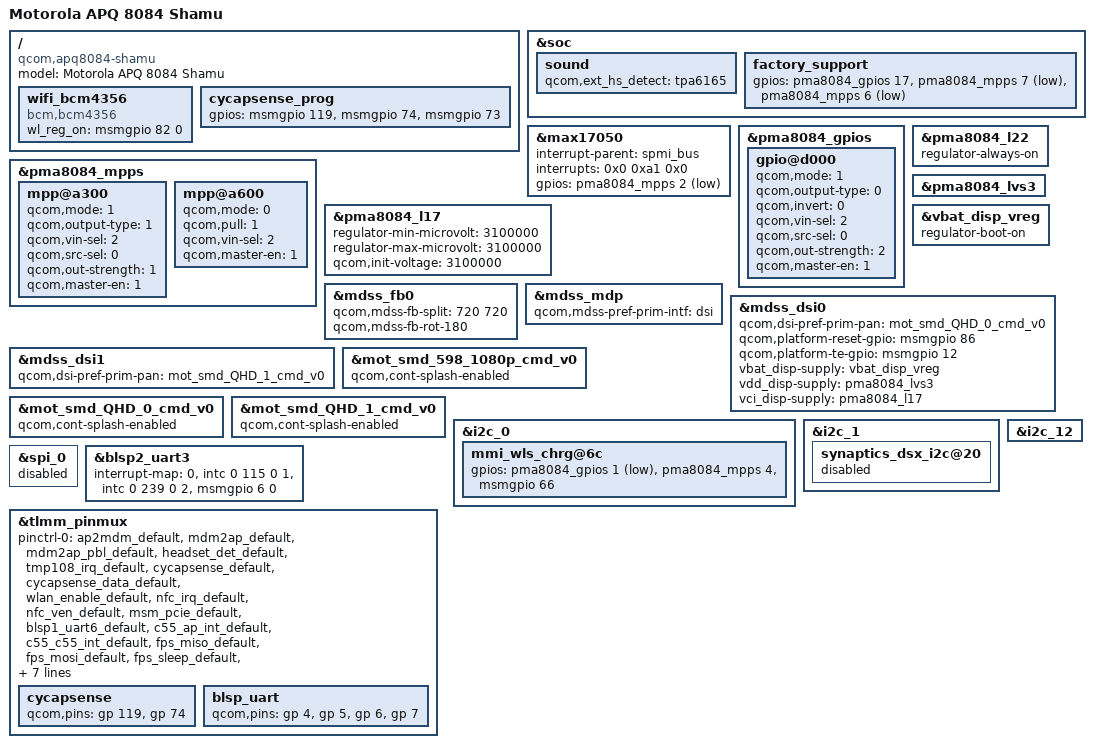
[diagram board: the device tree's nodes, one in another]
/* Copyright (c) 2013, The Linux Foundation. All rights reserved.
 * Copyright (c) 2014 Motorola Mobility LLC
 *
 * This program is free software; you can redistribute it and/or modify
 * it under the terms of the GNU General Public License version 2 and
 * only version 2 as published by the Free Software Foundation.
 *
 * This program is distributed in the hope that it will be useful,
 * but WITHOUT ANY WARRANTY; without even the implied warranty of
 * MERCHANTABILITY or FITNESS FOR A PARTICULAR PURPOSE.  See the
 * GNU General Public License for more details.
 */

#include "apq8084-moto-common.dtsi"
#include "dsi-panel-mot-dummy-qhd-video.dtsi"
#include "dsi-panel-mot-smd-QHD-cmd.dtsi"
#include "dsi-panel-mot-smd-598-1080p-cmd.dtsi"

/ {
	model = "Motorola APQ 8084 Shamu";
	compatible = "qcom,apq8084-shamu",
		   "qcom,apq8084-moto",
		   "qcom,apq8084";

	wifi_bcm4356 {
		compatible = "bcm,bcm4356";
		wl_reg_on = <&msmgpio 82 0>;
	};

	cycapsense_prog {
			gpios = <&msmgpio 119 0>, /* RESET */
				<&msmgpio 74 0>, /* programming SCLK */
				<&msmgpio 73 0>; /* programming SDAT */
	};

	/delete-node/ bt_qca6174;
};

&soc {
	sound {
		qcom,ext_hs_detect = "tpa6165";
	};

	factory_support {
		gpios = <&pma8084_gpios 17 0x0>, /* GPIOF_OUT_INIT_LOW */
			<&pma8084_mpps 7 0x1>, /* GPIOF_IN */
			<&pma8084_mpps 6 0x1>; /* GPIOF_IN */
	};

	/delete-node/ qcom,cnss@0d400000;
	/delete-node/ qca,qca1530;
};

&max17050 {
	interrupt-parent = <&spmi_bus>;
	interrupts = <0x0 0xa1 0x0>;    /* PMA8084 MPP 2 */
	gpios = <&pma8084_mpps 2 0x11>;  /* GPIOF_DIR_IN|GPIOF_EXPORT */
};

&pma8084_gpios {
	gpio@d000 { /* GPIO 17 */
		qcom,mode = <1>;		/* Digital output */
		qcom,output-type = <0>;		/* CMOS logic */
		qcom,invert = <0>;		/* Output low initially */
		qcom,vin-sel = <2>;		/* VIN 2 */
		qcom,src-sel = <0>;		/* GPIO */
		qcom,out-strength = <2>;	/* Medium */
		qcom,master-en = <1>;		/* Enable GPIO */
	};
};

&pma8084_mpps {
	mpp@a300 { /* MPP 4 */
		/* Wireless Charge Complete N */
		qcom,mode = <1>;		/* Digital output */
		qcom,output-type = <1>;		/* Open Drain NMOS logic */
		qcom,vin-sel = <2>;		/* VIN 2 */
		qcom,src-sel = <0>;		/* Constant */
		qcom,out-strength = <1>;	/* Low */
		qcom,master-en = <1>;		/* Enable GPIO */
	};
	mpp@a600 { /* MPP 7 */
		qcom,mode = <0>;          /* QPNP_PIN_MODE_DIG_IN */
		qcom,pull = <1>;	/* No pull */
		qcom,vin-sel = <2>;
		qcom,master-en = <1>;
	};
};
&pma8084_l22 {
	regulator-always-on;
};

&pma8084_l17 {
	regulator-min-microvolt = <3100000>;
	regulator-max-microvolt = <3100000>;
	qcom,init-voltage = <3100000>;
	/delete-property/ regulator-always-on;
};

&pma8084_lvs3 {
	/delete-property/ regulator-always-on;
};

&mdss_fb0 {
	qcom,mdss-fb-split = <720 720>;
	qcom,mdss-fb-rot-180;
};

&mdss_mdp {
	qcom,mdss-pref-prim-intf = "dsi";
};

&vbat_disp_vreg {
	regulator-boot-on;
};

&mdss_dsi0 {
	qcom,dsi-pref-prim-pan = <&mot_smd_QHD_0_cmd_v0>;
	qcom,platform-reset-gpio = <&msmgpio 86 0>;
	qcom,platform-te-gpio = <&msmgpio 12 0>;
	vbat_disp-supply = <&vbat_disp_vreg>;
	vdd_disp-supply = <&pma8084_lvs3>;
	vci_disp-supply = <&pma8084_l17>;
	/delete-property/ vdd-supply;
	/delete-node/ qcom,platform-supply-entry1;
};

&mdss_dsi1 {
	qcom,dsi-pref-prim-pan = <&mot_smd_QHD_1_cmd_v0>;
	/delete-property/ vdd-supply;
	/delete-node/ qcom,platform-supply-entry1;
};

&mot_smd_598_1080p_cmd_v0 {
	qcom,cont-splash-enabled;
};

&mot_smd_QHD_0_cmd_v0 {
	qcom,cont-splash-enabled;
};

&mot_smd_QHD_1_cmd_v0 {
	qcom,cont-splash-enabled;
};

&i2c_0 {
	mmi_wls_chrg@6c {
		gpios = <&pma8084_gpios 1 0x1>, /* GPIOF_IN */
			<&pma8084_mpps 4 0x2>, /* GPIOF_OUT_INIT_HIGH */
			<&msmgpio 66 0x0>; /* GPIOF_OUT_INIT_LOW */
	};
};

&i2c_1 {
	synaptics_dsx_i2c@20 {
		status = "disabled";
	};
};

&i2c_12 {
	/delete-node/ stm401@39;
};

&spi_0 {
	status = "disabled";
};

&blsp2_uart3 {
	interrupt-map = <0 &intc 0 115 0
			1 &intc 0 239 0
			2 &msmgpio 6 0>;
};

&tlmm_pinmux {
	pinctrl-0 =	 <
			&ap2mdm_default
			&mdm2ap_default
			&mdm2ap_pbl_default
			&headset_det_default
			&tmp108_irq_default
			&cycapsense_default
			&cycapsense_data_default
			&wlan_enable_default
			&nfc_irq_default
			&nfc_ven_default
			&msm_pcie_default
			&blsp1_uart6_default
			&c55_ap_int_default
			&c55_c55_int_default
			&fps_miso_default
			&fps_mosi_default
			&fps_sleep_default
			&fps_drdy_default
			&blsp_i2c_default
			&blsp_uart_default
			&blsp_uart_weak_default
			&blsp_spi_default
			&cam_mclk1_default
			&cam_mclk3_default
			&cam2_pwdn_default
			&max17050_default
			&factory_default
			&factory_kill_default
			&unused_default
			&disp_v1_en_default
			&ter_auxpcm_default
		>;

	cycapsense {
		qcom,pins = <&gp 119 &gp 74>;
	};

	blsp_uart  {
		qcom,pins = <&gp 4 &gp 5 &gp 6 &gp 7>;
	};
};
